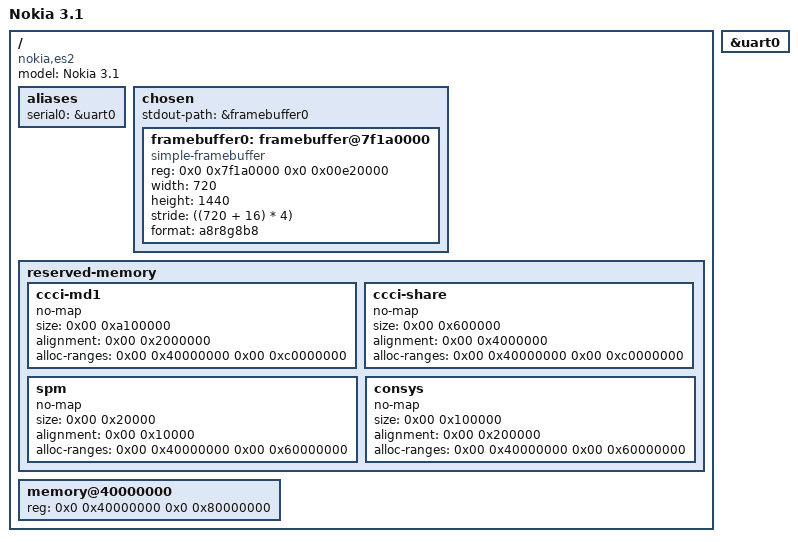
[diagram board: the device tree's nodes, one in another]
// SPDX-License-Identifier: GPL-2.0
/*
 * Device Tree Source for Nokia 3.1 (ES2)
 *
 * Copyright (C) 2023 Arseniy Velikanov <adomerlee@gmail.com>
 */

/dts-v1/;

#include "mt6755.dtsi"

/ {
	/* NOTE: if /model is defined the bootloader replaces it with "MT6750*" forcefully */
	model = "Nokia 3.1";
	compatible = "nokia,es2", "mediatek,mt6755";

	aliases {
		serial0 = &uart0;
	};

	chosen {
		stdout-path = &framebuffer0;

		/*
		 * HACK: Use display framebuffer setup by the lk bootloader for simplefb
		 * FIXME: only text is rendered on VT (TTY) as an unknown bit has to be flipped to disable
		 *        image compression!
		 */
		framebuffer0: framebuffer@7f1a0000 {
			compatible = "simple-framebuffer";
			reg = <0x0 0x7f1a0000 0x0 0x00e20000>;
			width = <720>;
			height = <1440>;
			stride = <((720 + 16) * 4)>;
			format = "a8r8g8b8";
		};
	};

	/* /reserved-memory has to exist even if practically empty or bootloader will be unhappy */
	reserved-memory {
		#address-cells = <2>;
		#size-cells = <2>;
		ranges;

		ccci-md1 {
			no-map;
			size = <0x00 0xa100000>;
			alignment = <0x00 0x2000000>;
			alloc-ranges = <0x00 0x40000000 0x00 0xc0000000>;
		};

		ccci-share {
			no-map;
			size = <0x00 0x600000>;
			alignment = <0x00 0x4000000>;
			alloc-ranges = <0x00 0x40000000 0x00 0xc0000000>;
		};

		spm {
			no-map;
			size = <0x00 0x20000>;
			alignment = <0x00 0x10000>;
			alloc-ranges = <0x00 0x40000000 0x00 0x60000000>;
		};

		consys {
			no-map;
			size = <0x00 0x100000>;
			alignment = <0x00 0x200000>;
			alloc-ranges = <0x00 0x40000000 0x00 0x60000000>;
		};
	};

	memory@40000000 {
		device_type = "memory";
		reg = <0x0 0x40000000 0x0 0x80000000>;
	};
};

&uart0 {
	status = "okay";
};
